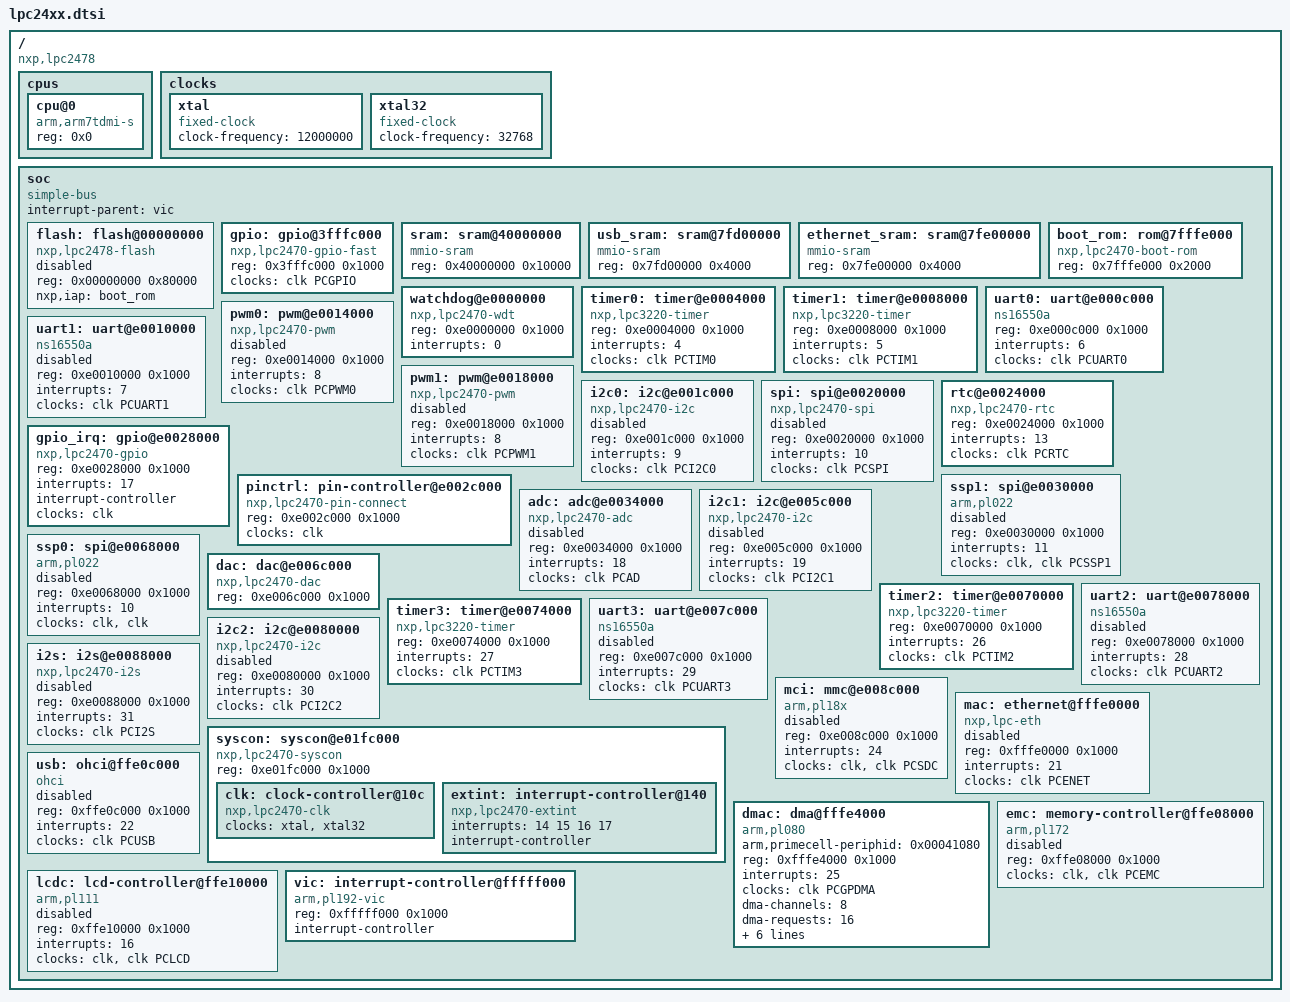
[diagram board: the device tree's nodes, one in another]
/*
 * Common base for NXP LPC24xx devices.
 *
 * Copyright 2015 Joachim Eastwood <manabian@gmail.com>
 *
 * This code is released using a dual license strategy: BSD/GPL
 * You can choose the licence that better fits your requirements.
 *
 * Released under the terms of 3-clause BSD License
 * Released under the terms of GNU General Public License Version 2.0
 *
 */

#include "skeleton.dtsi"

/ {
	compatible = "nxp,lpc2478", "nxp,lpc2470";

	cpus {
		#address-cells = <1>;
		#size-cells = <0>;

		cpu@0 {
			compatible = "arm,arm7tdmi-s";
			device_type = "cpu";
			reg = <0x0>;
		};
	};

	clocks {
		xtal: xtal {
			compatible = "fixed-clock";
			#clock-cells = <0>;
			clock-frequency = <12000000>;
		};

		xtal32: xtal32 {
			compatible = "fixed-clock";
			#clock-cells = <0>;
			clock-frequency = <32768>;
		};
	};

	soc {
		compatible = "simple-bus";
		interrupt-parent = <&vic>;
		#address-cells = <1>;
		#size-cells = <1>;
		ranges;

		flash: flash@00000000 {
			compatible = "nxp,lpc2478-flash";
			reg = <0x00000000 0x80000>;
			nxp,iap = <&boot_rom>;
			status = "disabled";
		};

		gpio: gpio@3fffc000 {
			compatible = "nxp,lpc2470-gpio-fast";
			reg = <0x3fffc000 0x1000>;
			clocks = <&clk PCGPIO>
			gpio-controller;
                        #gpio-cells = <2>;
		};

		sram: sram@40000000 {
			compatible = "mmio-sram";
			reg = <0x40000000 0x10000>; /* 64 KiB SRAM */
		};

		usb_sram: sram@7fd00000 {
			compatible = "mmio-sram";
			reg = <0x7fd00000 0x4000>; /* 16 KiB SRAM */
		};

		ethernet_sram: sram@7fe00000 {
			compatible = "mmio-sram";
			reg = <0x7fe00000 0x4000>; /* 16 KiB SRAM */
		};

		boot_rom: rom@7fffe000 {
			compatible = "nxp,lpc2470-boot-rom";
			reg = <0x7fffe000 0x2000>;
		};

		/* APB peripherals */
		watchdog@e0000000 {
			compatible = "nxp,lpc2470-wdt";
			reg = <0xe0000000 0x1000>;
			interrupts = <0>;
		};

		timer0: timer@e0004000 {
			compatible = "nxp,lpc3220-timer";
			reg = <0xe0004000 0x1000>;
			interrupts = <4>;
			clocks = <&clk PCTIM0>;
		};

		timer1: timer@e0008000 {
			compatible = "nxp,lpc3220-timer";
			reg = <0xe0008000 0x1000>;
			interrupts = <5>;
			clocks = <&clk PCTIM1>;
		};

		uart0: uart@e000c000 {
			compatible = "ns16550a";
			reg = <0xe000c000 0x1000>;
			interrupts = <6>;
			clocks = <&clk PCUART0>;
		};

		uart1: uart@e0010000 {
			compatible = "ns16550a";
			reg = <0xe0010000 0x1000>;
			interrupts = <7>;
			clocks = <&clk PCUART1>;
			status = "disabled";
		};

		pwm0: pwm@e0014000 {
			compatible = "nxp,lpc2470-pwm";
			reg = <0xe0014000 0x1000>;
			interrupts = <8>;
			clocks = <&clk PCPWM0>;
			status = "disabled";
		};

		pwm1: pwm@e0018000 {
			compatible = "nxp,lpc2470-pwm";
			reg = <0xe0018000 0x1000>;
			interrupts = <8>;
			clocks = <&clk PCPWM1>;
			status = "disabled";
		};

		i2c0: i2c@e001c000 {
			compatible = "nxp,lpc2470-i2c";
			reg = <0xe001c000 0x1000>;
			interrupts = <9>;
			clocks = <&clk PCI2C0>;
			status = "disabled";
		};

		spi: spi@e0020000 {
			compatible = "nxp,lpc2470-spi";
			reg = <0xe0020000 0x1000>;
			interrupts = <10>;
			clocks = <&clk PCSPI>;
			status = "disabled";
		};

		rtc@e0024000 {
			compatible = "nxp,lpc2470-rtc";
			reg = <0xe0024000 0x1000>;
			interrupts = <13>;
			clocks = <&clk PCRTC>;
		};

		gpio_irq: gpio@e0028000 {
			compatible = "nxp,lpc2470-gpio";
			reg = <0xe0028000 0x1000>;
			interrupts = <17>;
			interrupt-controller;
			#interrupt-cells = <2>;
			clocks = <&clk >;
		};

		pinctrl: pin-controller@e002c000 {
			compatible = "nxp,lpc2470-pin-connect";
			reg = <0xe002c000 0x1000>;
			clocks = <&clk >;
		};

		ssp1: spi@e0030000 {
			compatible = "arm,pl022", "arm,primecell";
			reg = <0xe0030000 0x1000>;
			interrupts = <11>;
			clocks = <&clk >, <&clk PCSSP1>;
			clock-names = "sspclk", "apb_pclk";
			#address-cells = <1>;
			#size-cells = <0>;
			status = "disabled";
		};

		adc: adc@e0034000 {
			compatible = "nxp,lpc2470-adc";
			reg = <0xe0034000 0x1000>;
			interrupts = <18>;
			clocks = <&clk PCAD>;
			status = "disabled";
		};

		/* Add CAN controllers (SJA1000) */

		i2c1: i2c@e005c000 {
			compatible = "nxp,lpc2470-i2c";
			reg = <0xe005c000 0x1000>;
			interrupts = <19>;
			clocks = <&clk PCI2C1>;
			status = "disabled";
		};

		ssp0: spi@e0068000 {
			compatible = "arm,pl022", "arm,primecell";
			reg = <0xe0068000 0x1000>;
			interrupts = <10>;
			clocks = <&clk >, <&clk >;
			clock-names = "sspclk", "apb_pclk";
			#address-cells = <1>;
			#size-cells = <0>;
			status = "disabled";
		};

		dac: dac@e006c000 {
			compatible = "nxp,lpc2470-dac";
			reg = <0xe006c000 0x1000>;
		};

		timer2: timer@e0070000 {
			compatible = "nxp,lpc3220-timer";
			reg = <0xe0070000 0x1000>;
			interrupts = <26>;
			clocks = <&clk PCTIM2>;
		};

		timer3: timer@e0074000 {
			compatible = "nxp,lpc3220-timer";
			reg = <0xe0074000 0x1000>;
			interrupts = <27>;
			clocks = <&clk PCTIM3>;
		};

		uart2: uart@e0078000 {
			compatible = "ns16550a";
			reg = <0xe0078000 0x1000>;
			interrupts = <28>;
			clocks = <&clk PCUART2>;
			status = "disabled";
		};

		uart3: uart@e007c000 {
			compatible = "ns16550a";
			reg = <0xe007c000 0x1000>;
			interrupts = <29>;
			clocks = <&clk PCUART3>;
			status = "disabled";
		};

		i2c2: i2c@e0080000 {
			compatible = "nxp,lpc2470-i2c";
			reg = <0xe0080000 0x1000>;
			interrupts = <30>;
			clocks = <&clk PCI2C2>;
			status = "disabled";
		};

		i2s: i2s@e0088000 {
			compatible = "nxp,lpc2470-i2s";
			reg = <0xe0088000 0x1000>;
			interrupts = <31>;
			clocks = <&clk PCI2S>;
			status = "disabled";
		};

		mci: mmc@e008c000 {
			compatible = "arm,pl18x", "arm,primecell";
			reg = <0xe008c000 0x1000>;
			interrupts = <24>;
			clocks = <&clk >, <&clk PCSDC>;
			clock-names = "sdi", "apb_pclk";
			status = "disabled";
		};

		syscon: syscon@e01fc000 {
			compatible = "nxp,lpc2470-syscon", "syscon", "simple-mfd";
			reg = <0xe01fc000 0x1000>;

			clk: clock-controller@10c {
				compatible = "nxp,lpc2470-clk";
				clocks = <&xtal>, <&xtal32>;
				clock-names = "xtal", "xtal32";
				#clock-cells = <1>;
			};

			extint: interrupt-controller@140 {
				compatible = "nxp,lpc2470-extint";
				interrupts = <14 15 16 17>;
				interrupt-controller;
				#interrupt-cells = <2>;
			};
		};

		/* AHB peripherals */
		mac: ethernet@fffe0000 {
			compatible = "nxp,lpc-eth";
			reg = <0xfffe0000 0x1000>;
			interrupts = <21>;
			clocks = <&clk PCENET>;
			status = "disabled";
		};

		dmac: dma@fffe4000 {
			compatible = "arm,pl080", "arm,primecell";
			arm,primecell-periphid = <0x00041080>;
			reg = <0xfffe4000 0x1000>;
			interrupts = <25>;
			clocks = <&clk PCGPDMA>;
			clock-names = "apb_pclk";
			#dma-cells = <2>;
			dma-channels = <8>;
			dma-requests = <16>;
			lli-bus-interface-ahb1;
			lli-bus-interface-ahb2;
			mem-bus-interface-ahb1;
			mem-bus-interface-ahb2;
			memcpy-burst-size = <256>;
			memcpy-bus-width = <32>;
		};

		emc: memory-controller@ffe08000 {
			compatible = "arm,pl172", "arm,primecell";
			reg = <0xffe08000 0x1000>;
			clocks = <&clk >, <&clk PCEMC>;
			clock-names = "mpmcclk", "apb_pclk";
			#address-cells = <2>;
			#size-cells = <1>;
			ranges = <0 0 0x80000000 0x1000000
				  1 0 0x81000000 0x1000000
				  2 0 0x82000000 0x1000000
				  3 0 0x83000000 0x1000000>;
			status = "disabled";
		};

		usb: ohci@ffe0c000 {
			compatible = "ohci";
			reg = <0xffe0c000 0x1000>;
			interrupts = <22>;
			clocks = <&clk PCUSB>;
			status = "disabled";
		};

		lcdc: lcd-controller@ffe10000 {
			compatible = "arm,pl111", "arm,primecell";
			reg = <0xffe10000 0x1000>;
			interrupts = <16>;
			interrupt-names = "combined";
			clocks = <&clk >, <&clk PCLCD>;
			clock-names = "clcdclk", "apb_pclk";
			status = "disabled";
		};

		vic: interrupt-controller@fffff000 {
			compatible = "arm,pl192-vic"; /* pl192? */
			reg = <0xfffff000 0x1000>;
			interrupt-controller;
			#interrupt-cells = <1>;
		};
	};
};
